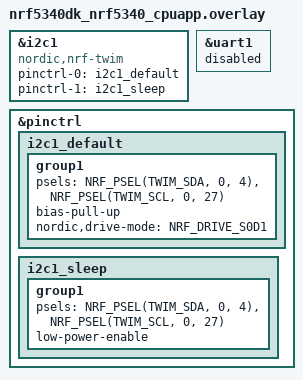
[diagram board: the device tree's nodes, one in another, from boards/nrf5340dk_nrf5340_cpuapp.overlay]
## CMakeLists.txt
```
#
# Copyright (c) 2018 Nordic Semiconductor
#
# SPDX-License-Identifier: LicenseRef-Nordic-5-Clause
#
cmake_minimum_required(VERSION 3.13.1)

find_package(Zephyr REQUIRED HINTS $ENV{ZEPHYR_BASE})
project(NONE)

# NORDIC SDK APP START
  
target_sources(app PRIVATE
  src/main.c
)

# NORDIC SDK APP END

zephyr_library_include_directories(.)
```

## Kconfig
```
#
# Copyright (c) 2018 Nordic Semiconductor
#
# SPDX-License-Identifier: LicenseRef-Nordic-5-Clause
#

source "Kconfig.zephyr"

menu "kconfig definition example"

config MACRO_EXAMPLE
	bool "define a macro CONFIG_MACRO_EXAMPLE"
	help
	  CONFIG_MACRO_EXAMPLE can be used globally in your application

endmenu
```

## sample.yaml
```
sample:
  name: i2c master
tests:
  sample.boards.nrf.nrfx:
    platform_allow: nrf52840dk_nrf52840 nrf9160dk_nrf9160_ns nrf5340dk_nrf5340_cpuapp
    tags: board
    harness: console
```

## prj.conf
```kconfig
#
# Copyright (c) 2018 Nordic Semiconductor
#
# SPDX-License-Identifier: LicenseRef-Nordic-5-Clause
#

# Enable DK LED and Buttons library
CONFIG_DK_LIBRARY=y

# This example requires more workqueue stack
CONFIG_SYSTEM_WORKQUEUE_STACK_SIZE=2048

# Config logger
CONFIG_LOG=y
CONFIG_LOG_PRINTK=y

CONFIG_I2C=y
CONFIG_NRFX_TWIM1=y

CONFIG_ASSERT=y
CONFIG_GPIO=y
## thread monitor ##
CONFIG_THREAD_ANALYZER=y
CONFIG_THREAD_NAME=y
```

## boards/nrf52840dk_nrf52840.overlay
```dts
/* overlay file */

my_i2c: &i2c1 {
	status = "okay";
	compatible = "nordic,nrf-twim";
	pinctrl-0 = < &i2c1_default >;
	pinctrl-1 = < &i2c1_sleep >;
	pinctrl-names = "default", "sleep";	
};

&pinctrl {

	i2c1_default: i2c1_default {
		group1 {
			psels = <NRF_PSEL(TWIM_SDA, 0, 4)>,
				<NRF_PSEL(TWIM_SCL, 0, 3)>;
			bias-pull-up;
			nordic,drive-mode = <NRF_DRIVE_S0D1>;
		};
	};

	i2c1_sleep: i2c1_sleep {
		group1 {
			psels = <NRF_PSEL(TWIM_SDA, 0, 4)>,
				<NRF_PSEL(TWIM_SCL, 0, 3)>;
			low-power-enable;
		};
	};	

};
```

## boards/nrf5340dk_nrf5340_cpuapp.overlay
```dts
/* overlay file */

my_i2c: &i2c1 {
	status = "okay";
	compatible = "nordic,nrf-twim";
	pinctrl-0 = < &i2c1_default >;
	pinctrl-1 = < &i2c1_sleep >;
	pinctrl-names = "default", "sleep";	
};

&uart1 {
	status = "disabled";
};

&pinctrl {

	i2c1_default: i2c1_default {
		group1 {
			psels = <NRF_PSEL(TWIM_SDA, 0, 4)>,
				<NRF_PSEL(TWIM_SCL, 0, 27)>;
			bias-pull-up;
			nordic,drive-mode = <NRF_DRIVE_S0D1>;	
		};
	};

	i2c1_sleep: i2c1_sleep {
		group1 {
			psels = <NRF_PSEL(TWIM_SDA, 0, 4)>,
				<NRF_PSEL(TWIM_SCL, 0, 27)>;
			low-power-enable;
		};
	};	

};
```

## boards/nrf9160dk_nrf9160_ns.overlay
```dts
/* overlay file */

my_i2c: &i2c1 {
	status = "okay";
	compatible = "nordic,nrf-twim";
	pinctrl-0 = < &i2c1_default >;
	pinctrl-1 = < &i2c1_sleep >;
	pinctrl-names = "default", "sleep";	
};

&uart1 {
	status = "disabled";
};

&pinctrl {

	i2c1_default: i2c1_default {
		group1 {
			psels = <NRF_PSEL(TWIM_SDA, 0, 18)>,
				<NRF_PSEL(TWIM_SCL, 0, 19)>;
			bias-pull-up;
			nordic,drive-mode = <NRF_DRIVE_S0D1>;		
		};
	};

	i2c1_sleep: i2c1_sleep {
		group1 {
			psels = <NRF_PSEL(TWIM_SDA, 0, 18)>,
				<NRF_PSEL(TWIM_SCL, 0, 19)>;
			low-power-enable;
		};
	};	

};
```

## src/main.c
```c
/*
 * Copyright (c) 2020 Nordic Semiconductor ASA
 *
 * SPDX-License-Identifier: LicenseRef-BSD-5-Clause-Nordic
 */

#include <zephyr/kernel.h>
#include <zephyr/device.h>
#include <zephyr/devicetree.h>
#include <zephyr/drivers/i2c.h>
#include <zephyr/logging/log.h>

#define LOG_MODULE_NAME main
LOG_MODULE_REGISTER(LOG_MODULE_NAME);

const struct device *i2c_dev;

#define EEPROM_SIM_SIZE                   (320u) //!< Simulated EEPROM size.

#define EEPROM_SIM_ADDR                   0x50    //!< Simulated EEPROM TWI slave address.

/* Slave memory addressing byte length */
#define EEPROM_SIM_ADDRESS_LEN_BYTES    2

#define IN_LINE_PRINT_CNT   (16u)   //!< Number of data bytes printed in a single line.


static int eeprom_read(uint16_t addr, uint8_t * pdata, size_t size)
{
    int ret;
    if (size > (EEPROM_SIM_SIZE))
    {
        return EINVAL;
    }
    do
    {
       uint16_t addr16 = addr;
       ret = i2c_write(i2c_dev, (uint8_t *)&addr16, EEPROM_SIM_ADDRESS_LEN_BYTES, EEPROM_SIM_ADDR);
       if (ret)
       {
           LOG_ERR("i2c_write err %d", ret);  
       }
      
       ret = i2c_read(i2c_dev, pdata, size, EEPROM_SIM_ADDR);
       if (ret)
       {
           LOG_ERR("i2c_read err %d", ret);  
       }
        // struct i2c_msg msg[2];

        // msg[0].buf = (uint8_t *)&addr;
        // msg[0].len = EEPROM_SIM_ADDRESS_LEN_BYTES;
        // msg[0].flags = I2C_MSG_WRITE | I2C_MSG_STOP;

        // msg[1].buf = pdata;
        // msg[1].len = size;
        // msg[1].flags = I2C_MSG_READ | I2C_MSG_STOP;

        // ret = i2c_transfer(i2c_dev, msg, 2, EEPROM_SIM_ADDR);
        // if (ret)
        // {
        //     LOG_ERR("i2c xfer err %d", ret);            
        // }

    } while(0);

    return ret;
}

static void eeprom_cmd_read(void)
{    
    uint8_t buf[IN_LINE_PRINT_CNT+1];

    for (uint16_t addr = 0; addr < EEPROM_SIM_SIZE; addr += IN_LINE_PRINT_CNT)
    {
        int err_code;
        err_code = eeprom_read(addr, buf, IN_LINE_PRINT_CNT);
        buf[IN_LINE_PRINT_CNT] = '\0';
        if (err_code)
        {
            LOG_ERR("EEPROM error %d", err_code);
            return;
        }

        LOG_HEXDUMP_INF(buf, IN_LINE_PRINT_CNT, "EEPROM: ");        
      
    }
}

void main(void)
{	
	
	LOG_INF("** I2C master example **");
	LOG_INF("This example is ported from nRF5_SDK\\examples\\peripheral\\twi_master_with_twis_slave");
	LOG_INF("The related twis example is from nRF5_SDK\\examples\\peripheral\\twi_master_with_twis_slave");	
	
	i2c_dev = device_get_binding(DT_NODE_FULL_NAME(DT_NODELABEL(my_i2c)));
	if (!i2c_dev) {
		LOG_ERR("I2C Device driver not found");
		return;
	}
    uint32_t i2c_cfg = I2C_SPEED_SET(I2C_SPEED_FAST) | I2C_MODE_CONTROLLER;
    if (i2c_configure(i2c_dev, i2c_cfg)) {
        LOG_ERR("I2C config failed");
        return;
    }  

	while (1) {		
		LOG_INF("i2c master thread"); 
        eeprom_cmd_read();
         k_sleep(K_SECONDS(2));        
	}
}
```
